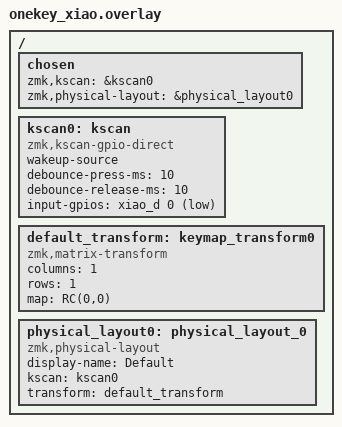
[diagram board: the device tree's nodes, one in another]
#include <dt-bindings/zmk/matrix_transform.h>

/ {
    chosen {
        zmk,kscan = &kscan0;
        zmk,physical-layout = &physical_layout0;
    };

    kscan0: kscan {
        compatible = "zmk,kscan-gpio-direct";
        wakeup-source;
        debounce-press-ms = <10>;
        debounce-release-ms = <10>;
        input-gpios = <&xiao_d 0 (GPIO_ACTIVE_LOW | GPIO_PULL_UP)>;
    };

    default_transform: keymap_transform0 {
        compatible = "zmk,matrix-transform";
        columns = <1>;
        rows = <1>;
        map = <
            RC(0,0)
        >;
    };

    physical_layout0: physical_layout_0 {
        compatible = "zmk,physical-layout";
        display-name = "Default";
        kscan = <&kscan0>;
        transform = <&default_transform>;
    };
};

